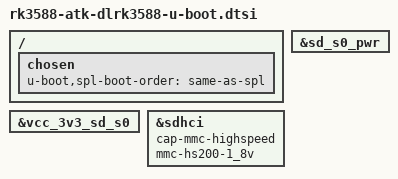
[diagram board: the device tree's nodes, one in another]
// SPDX-License-Identifier: (GPL-2.0+ OR MIT)
/*
 * Copyright (c) 2025 Alientek Electronics Co., Ltd
 */

#include "rk3588-u-boot.dtsi"

/ {
	chosen {
		u-boot,spl-boot-order = "same-as-spl", &sdmmc, &sdhci;
	};
};

&vcc_3v3_sd_s0 {
	bootph-pre-ram;
	bootph-some-ram;
};

&sd_s0_pwr {
	bootph-pre-ram;
	bootph-some-ram;
};

/* HS400 is unreliable in U-Boot; match other RK3588 boards. */
&sdhci {
	cap-mmc-highspeed;
	mmc-hs200-1_8v;
};
